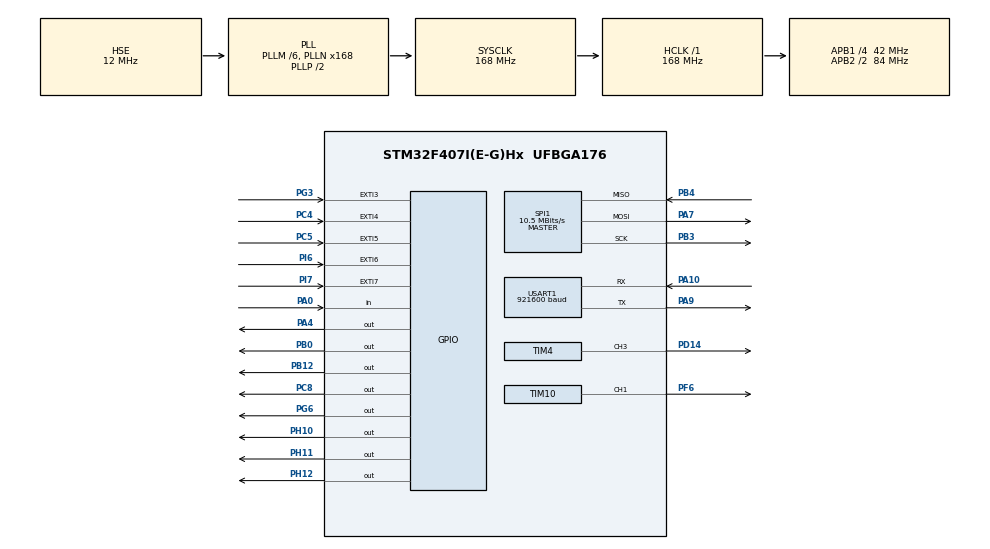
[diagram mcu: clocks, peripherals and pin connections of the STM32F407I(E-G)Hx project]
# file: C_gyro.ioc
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Dma.Request0=USART1_TX
Dma.Request1=SPI1_RX
Dma.Request2=SPI1_TX
Dma.SPI1_RX.1.Direction=DMA_PERIPH_TO_MEMORY
Dma.SPI1_RX.1.FIFOMode=DMA_FIFOMODE_DISABLE
Dma.SPI1_RX.1.Instance=DMA2_Stream0
Dma.SPI1_RX.1.MemDataAlignment=DMA_MDATAALIGN_BYTE
Dma.SPI1_RX.1.MemInc=DMA_MINC_ENABLE
Dma.SPI1_RX.1.Mode=DMA_NORMAL
Dma.SPI1_RX.1.PeriphDataAlignment=DMA_PDATAALIGN_BYTE
Dma.SPI1_RX.1.PeriphInc=DMA_PINC_DISABLE
Dma.SPI1_RX.1.Priority=DMA_PRIORITY_VERY_HIGH
Dma.SPI1_TX.2.Direction=DMA_MEMORY_TO_PERIPH
Dma.SPI1_TX.2.FIFOMode=DMA_FIFOMODE_DISABLE
Dma.SPI1_TX.2.Instance=DMA2_Stream3
Dma.SPI1_TX.2.MemDataAlignment=DMA_MDATAALIGN_BYTE
Dma.SPI1_TX.2.MemInc=DMA_MINC_ENABLE
Dma.SPI1_TX.2.Mode=DMA_NORMAL
Dma.SPI1_TX.2.PeriphDataAlignment=DMA_PDATAALIGN_BYTE
Dma.SPI1_TX.2.PeriphInc=DMA_PINC_DISABLE
Dma.SPI1_TX.2.Priority=DMA_PRIORITY_HIGH
Dma.USART1_TX.0.Direction=DMA_MEMORY_TO_PERIPH
Dma.USART1_TX.0.FIFOMode=DMA_FIFOMODE_DISABLE
Dma.USART1_TX.0.Instance=DMA2_Stream7
Dma.USART1_TX.0.MemDataAlignment=DMA_MDATAALIGN_BYTE
Dma.USART1_TX.0.MemInc=DMA_MINC_ENABLE
Dma.USART1_TX.0.Mode=DMA_NORMAL
Dma.USART1_TX.0.PeriphDataAlignment=DMA_PDATAALIGN_BYTE
Dma.USART1_TX.0.PeriphInc=DMA_PINC_DISABLE
Dma.USART1_TX.0.Priority=DMA_PRIORITY_VERY_HIGH
FREERTOS.Tasks01=defaultTask,24,128,StartDefaultTask,Default,NULL,Dynamic,NULL,NULL;imutask,16,1024,Imu_Task,As weak,NULL,Dynamic,NULL,NULL;sendtask,16,1024,Send_Task,As weak,NULL,Dynamic,NULL,NULL
Mcu.Family=STM32F4
Mcu.Name=STM32F407I(E-G)Hx
Mcu.Package=UFBGA176
NVIC.DMA2_Stream0_IRQn=true\:5\:0\:false\:false\:true\:true\:false\:true\:true
NVIC.DMA2_Stream3_IRQn=true\:5\:0\:false\:false\:true\:true\:false\:true\:true
NVIC.DMA2_Stream7_IRQn=true\:5\:0\:false\:false\:true\:true\:false\:true\:true
NVIC.PriorityGroup=NVIC_PRIORITYGROUP_4
NVIC.SPI1_IRQn=true\:5\:0\:false\:false\:true\:true\:true\:true\:true
NVIC.TIM8_TRG_COM_TIM14_IRQn=true\:15\:0\:false\:false\:true\:false\:false\:true\:true
NVIC.TimeBase=TIM8_TRG_COM_TIM14_IRQn
NVIC.TimeBaseIP=TIM14
NVIC.USART1_IRQn=true\:5\:0\:false\:false\:true\:true\:false\:true\:true
PA0-WKUP.GPIO_PuPd=GPIO_PULLUP
PA0-WKUP.Signal=GPIO_Input
PA10.Mode=Asynchronous
PA10.Signal=USART1_RX
PA13.Mode=Serial_Wire
PA13.Signal=SYS_JTMS-SWDIO
PA14.Mode=Serial_Wire
PA14.Signal=SYS_JTCK-SWCLK
PA4.GPIO_PuPd=GPIO_PULLUP
PA4.GPIO_Speed=GPIO_SPEED_FREQ_HIGH
PA4.PinState=GPIO_PIN_SET
PA4.Signal=GPIO_Output
PA7.Mode=Full_Duplex_Master
PA7.Signal=SPI1_MOSI
PA9.Mode=Asynchronous
PA9.Signal=USART1_TX
PB0.GPIO_PuPd=GPIO_PULLUP
PB0.GPIO_Speed=GPIO_SPEED_FREQ_HIGH
PB0.PinState=GPIO_PIN_SET
PB0.Signal=GPIO_Output
PB12.GPIO_PuPd=GPIO_PULLUP
PB12.GPIO_Speed=GPIO_SPEED_FREQ_MEDIUM
PB12.PinState=GPIO_PIN_SET
PB12.Signal=GPIO_Output
PB3.Mode=Full_Duplex_Master
PB3.Signal=SPI1_SCK
PB4.Mode=Full_Duplex_Master
PB4.Signal=SPI1_MISO
PC4.GPIO_PuPd=GPIO_PULLUP
PC4.Signal=GPXTI4
PC5.GPIO_PuPd=GPIO_PULLUP
PC5.Signal=GPXTI5
PC8.GPIO_PuPd=GPIO_NOPULL
PC8.Signal=GPIO_Output
PD14.GPIO_PuPd=GPIO_PULLUP
PD14.GPIO_Speed=GPIO_SPEED_FREQ_VERY_HIGH
PD14.Signal=S_TIM4_CH3
PF6.Signal=S_TIM10_CH1
PG3.GPIO_PuPd=GPIO_PULLUP
PG3.Signal=GPXTI3
PG6.GPIO_PuPd=GPIO_PULLUP
PG6.GPIO_Speed=GPIO_SPEED_FREQ_MEDIUM
PG6.PinState=GPIO_PIN_SET
PG6.Signal=GPIO_Output
PH0-OSC_IN.Mode=HSE-External-Oscillator
PH0-OSC_IN.Signal=RCC_OSC_IN
PH1-OSC_OUT.Mode=HSE-External-Oscillator
PH1-OSC_OUT.Signal=RCC_OSC_OUT
PH10.GPIO_PuPd=GPIO_PULLDOWN
PH10.PinState=GPIO_PIN_RESET
PH10.Signal=GPIO_Output
PH11.GPIO_PuPd=GPIO_PULLDOWN
PH11.Signal=GPIO_Output
PH12.GPIO_PuPd=GPIO_PULLDOWN
PH12.Signal=GPIO_Output
PI6.Signal=GPXTI6
PI7.Signal=GPXTI7
ProjectManager.HeapSize=0x2000
ProjectManager.StackSize=0x4000
ProjectManager.TargetToolchain=MDK-ARM V5.32
RCC.48MHZClocksFreq_Value=84000000
RCC.AHBFreq_Value=168000000
RCC.APB1CLKDivider=RCC_HCLK_DIV4
RCC.APB1Freq_Value=42000000
RCC.APB1TimFreq_Value=84000000
RCC.APB2CLKDivider=RCC_HCLK_DIV2
RCC.APB2Freq_Value=84000000
RCC.APB2TimFreq_Value=168000000
RCC.CortexFreq_Value=168000000
RCC.HCLKFreq_Value=168000000
RCC.HSE_VALUE=12000000
RCC.HSI_VALUE=16000000
RCC.LSE_VALUE=32768
RCC.PLLM=6
RCC.PLLN=168
RCC.PLLSourceVirtual=RCC_PLLSOURCE_HSE
RCC.SYSCLKFreq_VALUE=168000000
RCC.SYSCLKSource=RCC_SYSCLKSOURCE_PLLCLK
RCC.VCOOutputFreq_Value=336000000
SH.S_TIM10_CH1.0=TIM10_CH1,PWM Generation1 CH1
SH.S_TIM4_CH3.0=TIM4_CH3,PWM Generation3 CH3
SPI1.BaudRatePrescaler=SPI_BAUDRATEPRESCALER_8
SPI1.CLKPhase=SPI_PHASE_2EDGE
SPI1.CLKPolarity=SPI_POLARITY_HIGH
SPI1.CalculateBaudRate=10.5 MBits/s
SPI1.Direction=SPI_DIRECTION_2LINES
SPI1.Mode=SPI_MODE_MASTER
SPI1.VirtualType=VM_MASTER
TIM10.Channel=TIM_CHANNEL_1
TIM10.Period=2000-1
TIM10.Prescaler=84-1
TIM4.Channel-PWM\ Generation3\ CH3=TIM_CHANNEL_3
TIM4.Period=2000-1
TIM4.Prescaler=17
USART1.BaudRate=921600
USART1.VirtualMode=VM_ASYNC
VP_FREERTOS_VS_CMSIS_V2.Mode=CMSIS_V2
VP_SYS_VS_tim14.Mode=TIM14
VP_TIM10_VS_ClockSourceINT.Mode=Enable_Timer
board=custom

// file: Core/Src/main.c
/* USER CODE BEGIN Header */
/**
  ******************************************************************************
  * @file           : main.c
  * @brief          : Main program body
  ******************************************************************************
  * @attention
  *
  * Copyright (c) 2025 STMicroelectronics.
  * All rights reserved.
  *
  * This software is licensed under terms that can be found in the LICENSE file
  * in the root directory of this software component.
  * If no LICENSE file comes with this software, it is provided AS-IS.
  *
  ******************************************************************************
  */
/* USER CODE END Header */
#include "main.h"
#include "cmsis_os.h"
#include "dma.h"
#include "spi.h"
#include "tim.h"
#include "usart.h"
#include "gpio.h"

/* USER CODE BEGIN Includes */
#include "buzzer.h"
#include "BMI088driver.h"
#include "bsp_dwt.h"
/* USER CODE END Includes */

void SystemClock_Config(void);
void MX_FREERTOS_Init(void);

int main(void)
{

  /* MCU Configuration--------------------------------------------------------*/

  /* Reset of all peripherals, Initializes the Flash interface and the Systick. */
  HAL_Init();

  /* Configure the system clock */
  SystemClock_Config();

  /* Initialize all configured peripherals */
  MX_GPIO_Init();
  MX_DMA_Init();
  MX_USART1_UART_Init();
  MX_SPI1_Init();
  MX_TIM10_Init();
  MX_TIM4_Init();
  /* USER CODE BEGIN 2 */
	Start_Buzzer_remind2();
	HAL_GPIO_WritePin(GPIOH,GPIO_PIN_12,GPIO_PIN_SET);
  DWT_Init(168);
  while (BMI088_init(&hspi1, 1) != BMI088_NO_ERROR)
        ;
  /* USER CODE END 2 */

  /* Init scheduler */
  osKernelInitialize();

  /* Call init function for freertos objects (in cmsis_os2.c) */
  MX_FREERTOS_Init();

  /* Start scheduler */
  osKernelStart();

  /* We should never get here as control is now taken by the scheduler */

  /* Infinite loop */
  while (1)
  {

  }
}

void SystemClock_Config(void)
{
  RCC_OscInitTypeDef RCC_OscInitStruct = {0};
  RCC_ClkInitTypeDef RCC_ClkInitStruct = {0};

  /** Configure the main internal regulator output voltage
  */
  __HAL_RCC_PWR_CLK_ENABLE();
  __HAL_PWR_VOLTAGESCALING_CONFIG(PWR_REGULATOR_VOLTAGE_SCALE1);

  /** Initializes the RCC Oscillators according to the specified parameters
  * in the RCC_OscInitTypeDef structure.
  */
  RCC_OscInitStruct.OscillatorType = RCC_OSCILLATORTYPE_HSE;
  RCC_OscInitStruct.HSEState = RCC_HSE_ON;
  RCC_OscInitStruct.PLL.PLLState = RCC_PLL_ON;
  RCC_OscInitStruct.PLL.PLLSource = RCC_PLLSOURCE_HSE;
  RCC_OscInitStruct.PLL.PLLM = 6;
  RCC_OscInitStruct.PLL.PLLN = 168;
  RCC_OscInitStruct.PLL.PLLP = RCC_PLLP_DIV2;
  RCC_OscInitStruct.PLL.PLLQ = 4;
  if (HAL_RCC_OscConfig(&RCC_OscInitStruct) != HAL_OK)
  {
    Error_Handler();
  }

  /** Initializes the CPU, AHB and APB buses clocks
  */
  RCC_ClkInitStruct.ClockType = RCC_CLOCKTYPE_HCLK|RCC_CLOCKTYPE_SYSCLK
                              |RCC_CLOCKTYPE_PCLK1|RCC_CLOCKTYPE_PCLK2;
  RCC_ClkInitStruct.SYSCLKSource = RCC_SYSCLKSOURCE_PLLCLK;
  RCC_ClkInitStruct.AHBCLKDivider = RCC_SYSCLK_DIV1;
  RCC_ClkInitStruct.APB1CLKDivider = RCC_HCLK_DIV4;
  RCC_ClkInitStruct.APB2CLKDivider = RCC_HCLK_DIV2;

  if (HAL_RCC_ClockConfig(&RCC_ClkInitStruct, FLASH_LATENCY_5) != HAL_OK)
  {
    Error_Handler();
  }
}

void HAL_TIM_PeriodElapsedCallback(TIM_HandleTypeDef *htim)
{
  if (htim->Instance == TIM14) {
    HAL_IncTick();
  }
}

void Error_Handler(void)
{
  __disable_irq();
  while (1)
  {
  }
}

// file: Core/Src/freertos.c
/* USER CODE BEGIN Header */
/**
  ******************************************************************************
  * File Name          : freertos.c
  * Description        : Code for freertos applications
  ******************************************************************************
  * @attention
  *
  * Copyright (c) 2025 STMicroelectronics.
  * All rights reserved.
  *
  * This software is licensed under terms that can be found in the LICENSE file
  * in the root directory of this software component.
  * If no LICENSE file comes with this software, it is provided AS-IS.
  *
  ******************************************************************************
  */
/* USER CODE END Header */

#include "FreeRTOS.h"
#include "task.h"
#include "main.h"
#include "cmsis_os.h"

/* USER CODE BEGIN Includes */
#include "ins_task.h"
/* USER CODE END Includes */

/* Definitions for defaultTask */
osThreadId_t defaultTaskHandle;
const osThreadAttr_t defaultTask_attributes = {
  .name = "defaultTask",
  .stack_size = 128 * 4,
  .priority = (osPriority_t) osPriorityNormal,
};
/* Definitions for imutask */
osThreadId_t imutaskHandle;
const osThreadAttr_t imutask_attributes = {
  .name = "imutask",
  .stack_size = 1024 * 4,
  .priority = (osPriority_t) osPriorityBelowNormal,
};
/* Definitions for sendtask */
osThreadId_t sendtaskHandle;
const osThreadAttr_t sendtask_attributes = {
  .name = "sendtask",
  .stack_size = 1024 * 4,
  .priority = (osPriority_t) osPriorityBelowNormal,
};

void StartDefaultTask(void *argument);
void Imu_Task(void *argument);
void Send_Task(void *argument);

void MX_FREERTOS_Init(void); /* (MISRA C 2004 rule 8.1) */

void MX_FREERTOS_Init(void) {

  /* Create the thread(s) */
  /* creation of defaultTask */
  defaultTaskHandle = osThreadNew(StartDefaultTask, NULL, &defaultTask_attributes);

  /* creation of imutask */
  imutaskHandle = osThreadNew(Imu_Task, NULL, &imutask_attributes);

  /* creation of sendtask */
  sendtaskHandle = osThreadNew(Send_Task, NULL, &sendtask_attributes);

}

void StartDefaultTask(void *argument)
{
  for(;;)
  {
    osDelay(1);
  }
}

__weak void Imu_Task(void *argument)
{
  /* USER CODE BEGIN Imu_Task */
	INS_Init();
  /* Infinite loop */

  for(;;)
  {
		INS_Task();
    osDelay(1);
  }
  /* USER CODE END Imu_Task */
}

__weak void Send_Task(void *argument)
{
  for(;;)
  {
    osDelay(1);
  }
}
